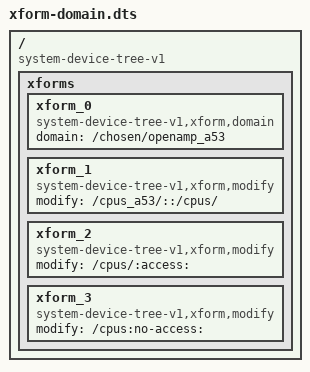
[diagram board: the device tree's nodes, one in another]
/dts-v1/;

/ {
        compatible = "system-device-tree-v1";
        xforms {
                // compatible = "system-device-tree-v1,xform";
                xform_0 {
                        compatible = "system-device-tree-v1,xform,domain";
                        domain = "/chosen/openamp_a53";
                };
                xform_1 {
                        // node name modify
                        compatible = "system-device-tree-v1,xform,modify";
                        modify = "/cpus_a53/::/cpus/";
                };
                xform_2 {
                        compatible = "system-device-tree-v1,xform,modify";
                        // format is: "path":"property":"replacement"
                        //    - modify to "nothing", is a remove operation
                        //    - modify with no property is node operation (rename or remove)
                        modify = "/cpus/:access:";
                };
                xform_3 {
                        // modify to "nothing", is a remove operation
                        compatible = "system-device-tree-v1,xform,modify";
                        modify = "/cpus:no-access:";
                };
        };
};
